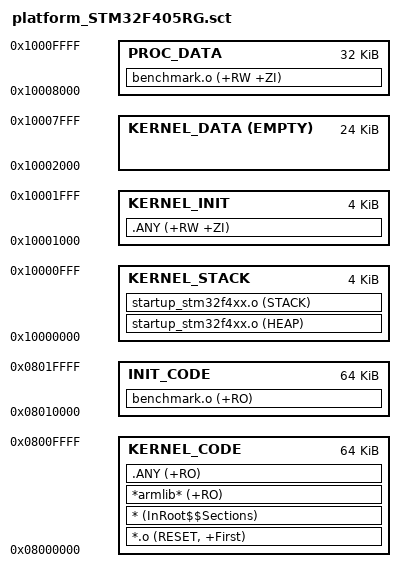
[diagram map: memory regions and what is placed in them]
;******************************************************************************
;Filename    : platform_STM32F405RG.sct
;Author      : pry
;Date        : 24/06/2017
;Licence     : LGPL v3+; see COPYING for details.
;Description : The scatter file for Cortex-M4 layout. This file is intended 
;              to be used with STM32F405RGT6.
;              ROM: 0x08000000 0x00100000
;              CCM: 0x10000000 0x00010000
;              RAM: 0x20000000 0x00020000
;              System ROM layout:
;              |0x08000000            0x0800FFFF|0x08010000         0x080FFFFF|
;              |<-           Kernel           ->|<-           User          ->|
;              System RAM layout:
;              |0x10000000            0x10001FFF|0x10002000         0x10003FFF|
;              |<-        Kernel Stack        ->|<-        Kernel Data      ->|
;              |0x10004000            0x1000FFFF|0x20000000         0x2001FFFF|
;              |<-       Kernel Objects       ->|<-           User          ->|
;******************************************************************************

; Begin Segment:KERNEL ********************************************************
; Description : The kernel segment, this is where the kernel of the operating
;               system is located at. This segment also contains the .bss(ZI)
;               for processes.
;               The kernel and the init process is placed in the CCMRAM.
; *****************************************************************************
KERNEL 0x08000000 0x00010000
{   
    ; Kernel code segment - 64kB
    KERNEL_CODE 0x08000000 0x00010000
    {   ; The reset vectors
        *.o                            (RESET, +First)
        ; The lib code copying code
        *                              (InRoot$$Sections)
        ; The ARM C library code - all of them is here
        *armlib*                       (+RO)
        ; The kernel code section
        .ANY                           (+RO)
    }
    
    ; Kernel stack segment - 4kB
    KERNEL_STACK 0x10000000 0x00001000
    {
        startup_stm32f4xx.o          (HEAP)
        startup_stm32f4xx.o          (STACK)
    }
    
    ; Initial kernel data segment - 4kB 
    KERNEL_INIT 0x10001000 0x00001000
    {
        .ANY                           (+RW +ZI)
    }
    
    ; Dynamically managed kernel data segment - 24kB
    KERNEL_DATA 0x10002000 EMPTY 0x00006000
    {
        
    }
    
    ; The data section of the processes - The rest of the memory
    PROC_DATA 0x10008000 0x00008000
    {
        benchmark.o                    (+RW +ZI)
    }
}
; End Segment:KERNEL **********************************************************

; Begin Segment:INIT **********************************************************
; Description : The .text segment of process INIT. Init is the first process
;               in the system, and should act as a memory manager itself.
;               The .RODATA size if this process is 0x00010000.
; *****************************************************************************
INIT 0x08010000 0x00010000
{
    ; Init process code segment - 64kB
    INIT_CODE 0x08010000 0x00010000
    {
        benchmark.o                    (+RO)
    }
}
; End Segment:INIT ************************************************************

; End Of File *****************************************************************

; Copyright (C) Evo-Devo Instrum. All rights reserved *************************

